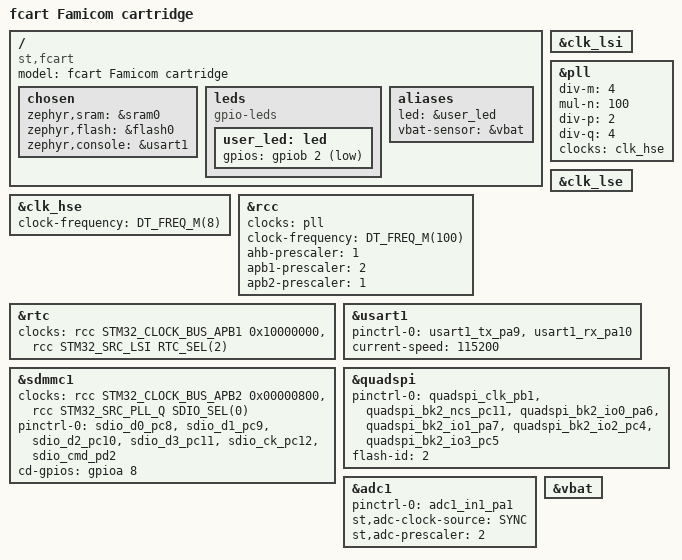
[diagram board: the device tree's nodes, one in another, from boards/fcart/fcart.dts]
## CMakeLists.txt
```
cmake_minimum_required(VERSION 3.20.0)
include(FetchContent)

set(BUILD_VERSION 3.7.1)
set(HAL_STM32_COMMIT f1317150eac951fdd8259337a47cbbc4c2e6d335)
set(CMSIS_COMMIT 4b96cbb174678dcd3ca86e11e1f24bc5f8726da0)
set(FATFS_COMMIT 427159bf95ea49b7680facffaa29ad506b42709b)
set(BOARD_ROOT ${CMAKE_CURRENT_SOURCE_DIR})
set(BOARD fcart)

set(NO_BUILD_TYPE_WARNING TRUE)
if(CMAKE_BUILD_TYPE STREQUAL "Debug")
    set(CONFIG_DEBUG y CACHE INTERNAL "Enable debug")
else()
    set(CONFIG_DEBUG n CACHE INTERNAL "Disable debug")
endif()

FetchContent_Declare(
    zephyr_distro
    DOWNLOAD_EXTRACT_TIMESTAMP TRUE
    URL https://github.com/zephyrproject-rtos/zephyr/archive/refs/tags/v${BUILD_VERSION}.tar.gz
    SOURCE_SUBDIR cmake # prevent cmake from being called inside the project
)
FetchContent_MakeAvailable(zephyr_distro)
FetchContent_Declare(
    hal_stm32
    DOWNLOAD_EXTRACT_TIMESTAMP TRUE
    URL https://github.com/zephyrproject-rtos/hal_stm32/archive/${HAL_STM32_COMMIT}.tar.gz
    SOURCE_SUBDIR cmake
    SOURCE_DIR "${CMAKE_CURRENT_BINARY_DIR}/modules/hal/stm32"
)
FetchContent_MakeAvailable(hal_stm32)
FetchContent_Declare(
    cmsis
    DOWNLOAD_EXTRACT_TIMESTAMP TRUE
    URL https://github.com/zephyrproject-rtos/cmsis/archive/${CMSIS_COMMIT}.tar.gz
    SOURCE_SUBDIR cmake
    SOURCE_DIR "${CMAKE_CURRENT_BINARY_DIR}/modules/hal/cmsis"
)
FetchContent_MakeAvailable(cmsis)
FetchContent_Declare(
    fatfs
    DOWNLOAD_EXTRACT_TIMESTAMP TRUE
    URL https://github.com/zephyrproject-rtos/fatfs/archive/${FATFS_COMMIT}.tar.gz
    SOURCE_SUBDIR cmake
    SOURCE_DIR "${CMAKE_CURRENT_BINARY_DIR}/modules/hal/fatfs"
)
FetchContent_MakeAvailable(fatfs)
set(ZEPHYR_MODULES ${hal_stm32_SOURCE_DIR} ${cmsis_SOURCE_DIR} ${fatfs_SOURCE_DIR})

find_package(Zephyr REQUIRED HINTS ${zephyr_distro_SOURCE_DIR})

project(fcart_sw)

add_subdirectory(src)
```

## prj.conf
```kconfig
CONFIG_LOG=y
CONFIG_SENSOR=y
CONFIG_ADC=y
```

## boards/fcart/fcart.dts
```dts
/dts-v1/;
#include <st/f4/stm32f412Xe.dtsi>
#include <st/f4/stm32f412r(e-g)tx-pinctrl.dtsi>

/ {
    model = "fcart Famicom cartridge";
    compatible = "st,fcart";

    chosen {
		zephyr,sram = &sram0;
		zephyr,flash = &flash0;
		zephyr,console = &usart1;
	};

    leds {
        compatible = "gpio-leds";
        user_led: led {
            gpios = <&gpiob 2 GPIO_ACTIVE_LOW>;
        };
    };

    aliases {
		led = &user_led;
		vbat-sensor = &vbat;
	};
};

&clk_lsi {
	status = "okay";
};

&clk_hse {
	clock-frequency = <DT_FREQ_M(8)>;
	status = "okay";
};

&pll {
	div-m = <4>;
	mul-n = <100>;
	div-p = <2>;
	div-q = <4>;
	clocks = <&clk_hse>;
	status = "okay";
};

&rcc {
	clocks = <&pll>;
	clock-frequency = <DT_FREQ_M(100)>;
	ahb-prescaler = <1>;
	apb1-prescaler = <2>;
	apb2-prescaler = <1>;
};

&clk_lse {
	status = "okay";
};

&rtc {
	clocks = <&rcc STM32_CLOCK_BUS_APB1 0x10000000>,
		 <&rcc STM32_SRC_LSI RTC_SEL(2)>;
	status = "okay";
};

&usart1 {
	pinctrl-0 = <&usart1_tx_pa9 &usart1_rx_pa10>;
	pinctrl-names = "default";
	current-speed = <115200>;
	status = "okay";
};

&sdmmc1 {
	clocks = <&rcc STM32_CLOCK_BUS_APB2 0x00000800>,
		<&rcc STM32_SRC_PLL_Q SDIO_SEL(0)>;
	status = "okay";
	pinctrl-0 = <&sdio_d0_pc8
		     &sdio_d1_pc9
		     &sdio_d2_pc10
		     &sdio_d3_pc11
		     &sdio_ck_pc12
		     &sdio_cmd_pd2>;
	pinctrl-names = "default";
	cd-gpios = <&gpioa 8 (GPIO_ACTIVE_HIGH | GPIO_PULL_UP)>;
};

&quadspi {
	pinctrl-0 = <&quadspi_clk_pb1 &quadspi_bk2_ncs_pc11
			&quadspi_bk2_io0_pa6 &quadspi_bk2_io1_pa7
		    &quadspi_bk2_io2_pc4 &quadspi_bk2_io3_pc5>;
	pinctrl-names = "default";
	flash-id = <2>;
	status = "okay";
};

&adc1 {
	pinctrl-0 = <&adc1_in1_pa1>;
	pinctrl-names = "default";
	st,adc-clock-source = <SYNC>;
	st,adc-prescaler = <2>;
	status = "okay";
};

&vbat {
	status = "okay";
};
```

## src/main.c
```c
#include "ui.h"
#include <ff.h>
#include <gpio.h>
#include <soc.h>
#include <tusb.h>

int main()
{
    hw_init();
    ui_init();

    for (;;) {
        gpio_poll();
        ui_poll();
        tud_task();
    }

    return 0;
}
```

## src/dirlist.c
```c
#include "dirlist.h"
#include "fpga_api.h"
#include "gfx.h"
#include <errno.h>
#include <ff.h>
#include <qspi.h>
#include <stdio.h>
#include <stdlib.h>
#include <string.h>

struct arr {
    uint32_t *items;
    uint16_t capacity;
    uint16_t count;
};

#define arr_append(a, v)                                               \
    do {                                                               \
        if (a.count >= a.capacity) {                                   \
            a.capacity = a.capacity == 0 ? 256 : a.capacity * 2;       \
            a.items = realloc(a.items, a.capacity * sizeof(*a.items)); \
        }                                                              \
        a.items[a.count++] = v;                                        \
    } while (0)

static struct arr items;
static uint16_t dir_count;
static char *curr_path;

typedef struct {
    uint32_t addr;
    char cache[11];
    uint8_t is_dir;
} cached_entry_t;

static int names_cmp(const void *a, const void *b);
static int readdir();

int dirlist_load()
{
    if (curr_path != NULL) {
        free(curr_path);
    }
    curr_path = malloc(1);
    curr_path[0] = '\0';

    return readdir();
}

int dirlist_push(const char *subdir)
{
    uint16_t subdir_len = strlen(subdir);
    uint16_t curr_path_len = strlen(curr_path);
    char *new_curr_path = malloc(curr_path_len + subdir_len + 2);
    if (new_curr_path == NULL) {
        return -ENOMEM;
    }

    strcpy(new_curr_path, curr_path);
    new_curr_path[curr_path_len] = '/';
    strcpy(&new_curr_path[curr_path_len + 1], subdir);

    free(curr_path);
    curr_path = new_curr_path;

    return readdir();
}

int dirlist_pop()
{
    char *last_slash = strrchr(curr_path, '/');
    if (last_slash != NULL) {
        *last_slash = '\0';
    } else {
        curr_path[0] = '\0';
    }
    return readdir();
}

uint16_t dirlist_size()
{
    return items.count;
}

uint8_t dirlist_select(uint16_t index, uint8_t limit, struct dirlist_entry *out)
{
    if (index >= items.count) {
        return 0; // Index out of bounds
    }

    uint8_t count = 0;
    uint16_t curr_index = index;

    while ((count < limit) && (curr_index < items.count)) {
        qspi_read(CMD_READ_MEM, items.items[curr_index], (uint8_t *)out[count].name, sizeof(out[count].name));
        out[count].is_dir = (curr_index < dir_count);

        count++;
        curr_index++;
    }
    return count; // Return number of entries filled
}

char *dirlist_file_path(struct dirlist_entry *entry)
{
    uint16_t curr_path_len = strlen(curr_path);
    uint16_t name_len = strlen(entry->name);
    char *full_path = malloc(curr_path_len + name_len + 2);
    if (full_path == NULL) {
        return NULL;
    }

    if (curr_path_len > 0) {
        strcpy(full_path, curr_path);
    }
    full_path[curr_path_len] = '/';
    strcpy(&full_path[curr_path_len + 1], entry->name);

    return full_path;
}

static int names_cmp(const void *a, const void *b)
{
    const cached_entry_t *ca = a;
    const cached_entry_t *cb = b;

    if (ca->is_dir != cb->is_dir) {
        return cb->is_dir - ca->is_dir;
    }

    int r = strncmp(ca->cache, cb->cache, sizeof(ca->cache));
    if (r != 0) {
        return r;
    }

    // Fallback to QSPI read
    char buf_a[256];
    char buf_b[256];
    qspi_read(CMD_READ_MEM, ca->addr, (uint8_t *)buf_a, sizeof(buf_a));
    qspi_read(CMD_READ_MEM, cb->addr, (uint8_t *)buf_b, sizeof(buf_b));
    return strcmp(buf_a, buf_b);
}

static int readdir()
{
    DIR dir;
    FILINFO fno;
    int r = 0;
    uint32_t sdram_addr = 0;

    if (f_opendir(&dir, curr_path) != FR_OK) {
        return false;
    }

    // Reset lists
    items.count = 0;
    dir_count = 0;

    struct {
        cached_entry_t *items;
        uint16_t capacity;
        uint16_t count;
    } cache_entries = { 0 };

    static uint8_t buf[512];
    uint16_t buf_len = 0;

    for (;;) {
        if (f_readdir(&dir, &fno) != FR_OK || fno.fname[0] == 0) {
            break;
        }
        if (fno.fname[0] == '.' || (fno.fattrib & AM_HID) || (fno.fattrib & AM_SYS)) {
            continue; // Skip hidden files
        }

        uint16_t name_len = strlen(fno.fname) + 1;
        uint16_t needed = name_len + (name_len % 2);

        if (buf_len + needed > sizeof(buf)) {
            if ((r = qspi_write(CMD_WRITE_MEM, sdram_addr, buf, buf_len)) != 0) {
                goto out;
            }
            sdram_addr += buf_len;
            buf_len = 0;
        }

        cached_entry_t entry;
        entry.addr = sdram_addr + buf_len;
        entry.is_dir = (fno.fattrib & AM_DIR) ? 1 : 0;
        memcpy(entry.cache, fno.fname, sizeof(entry.cache));

        arr_append(cache_entries, entry);
        if (cache_entries.items == NULL || cache_entries.count == UINT16_MAX) {
            r = -ENOSPC;
            goto out;
        }

        strcpy((char *)&buf[buf_len], fno.fname);
        if (needed > name_len)
            buf[buf_len + name_len] = 0;
        buf_len += needed;
    }

    if (buf_len > 0) {
        if ((r = qspi_write(CMD_WRITE_MEM, sdram_addr, buf, buf_len)) != 0) {
            goto out;
        }
    }

    if (cache_entries.count > 0)
        qsort(cache_entries.items, cache_entries.count, sizeof(cached_entry_t), names_cmp);

    for (uint16_t i = 0; i < cache_entries.count; i++) {
        arr_append(items, cache_entries.items[i].addr);
        if (cache_entries.items[i].is_dir) {
            dir_count++;
        }
    }
out:
    if (cache_entries.items)
        free(cache_entries.items);
    f_closedir(&dir);
    return r;
}
```

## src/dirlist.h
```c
#pragma once

#include <stdint.h>

struct dirlist_entry {
    char name[256];
    bool is_dir;
};

int dirlist_load();
int dirlist_push(const char *subdir);
int dirlist_pop();
uint16_t dirlist_size();
uint8_t dirlist_select(uint16_t index, uint8_t limit, struct dirlist_entry *out);
char *dirlist_file_path(struct dirlist_entry *entry);
```

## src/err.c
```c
#include "err.h"
#include <errno.h>

int fresult_to_errno(FRESULT rc)
{
    switch (rc) {
    case FR_OK:
        return 0;
    case FR_DISK_ERR:
        return EIO;
    case FR_INT_ERR:
        return EFAULT;
    case FR_NOT_READY:
        return EBUSY;
    case FR_NO_FILE:
        return ENOENT;
    case FR_NO_PATH:
        return ENOENT;
    case FR_INVALID_NAME:
        return EINVAL;
    case FR_DENIED:
        return EACCES;
    case FR_EXIST:
        return EEXIST;
    case FR_INVALID_OBJECT:
        return EINVAL;
    case FR_WRITE_PROTECTED:
        return EROFS;
    case FR_INVALID_DRIVE:
        return ENODEV;
    case FR_NOT_ENABLED:
        return ENODEV;
    case FR_NO_FILESYSTEM:
        return ENODEV;
    case FR_MKFS_ABORTED:
        return EIO;
    case FR_TIMEOUT:
        return ETIMEDOUT;
    case FR_LOCKED:
        return EBUSY;
    case FR_NOT_ENOUGH_CORE:
        return ENOMEM;
    case FR_TOO_MANY_OPEN_FILES:
        return EMFILE;
    case FR_INVALID_PARAMETER:
        return EINVAL;
    default:
        return EIO;
    }
}
```

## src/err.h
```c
#pragma once

#include <ff.h>

int fresult_to_errno(FRESULT rc);
```

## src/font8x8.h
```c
/**
 * Based on:
 *  Summary: font8x8.h
 *  8x8 monochrome bitmap fonts for rendering
 *
 *  Author:
 *      Marcel Sondaar
 *      International Business Machines (public domain VGA fonts)
 *
 *  License:
 *      Public Domain
 *
 * Fetched from: http://dimensionalrift.homelinux.net/combuster/mos3/?p=viewsource&file=/modules/gfx/font8_8.asm
 **/

const uint8_t font8x8[][8] = {
    { 0x00, 0x00, 0x00, 0x00, 0x00, 0x00, 0x00, 0x00 }, // U+0020 (space)
    { 0x18, 0x3C, 0x3C, 0x18, 0x18, 0x00, 0x18, 0x00 }, // U+0021 (!)
    { 0x36, 0x36, 0x00, 0x00, 0x00, 0x00, 0x00, 0x00 }, // U+0022 (")
    { 0x36, 0x36, 0x7F, 0x36, 0x7F, 0x36, 0x36, 0x00 }, // U+0023 (#)
    { 0x0C, 0x3E, 0x03, 0x1E, 0x30, 0x1F, 0x0C, 0x00 }, // U+0024 ($)
    { 0x00, 0x63, 0x33, 0x18, 0x0C, 0x66, 0x63, 0x00 }, // U+0025 (%)
    { 0x1C, 0x36, 0x1C, 0x6E, 0x3B, 0x33, 0x6E, 0x00 }, // U+0026 (&)
    { 0x06, 0x06, 0x03, 0x00, 0x00, 0x00, 0x00, 0x00 }, // U+0027 (')
    { 0x18, 0x0C, 0x06, 0x06, 0x06, 0x0C, 0x18, 0x00 }, // U+0028 (()
    { 0x06, 0x0C, 0x18, 0x18, 0x18, 0x0C, 0x06, 0x00 }, // U+0029 ())
    { 0x00, 0x66, 0x3C, 0xFF, 0x3C, 0x66, 0x00, 0x00 }, // U+002A (*)
    { 0x00, 0x0C, 0x0C, 0x3F, 0x0C, 0x0C, 0x00, 0x00 }, // U+002B (+)
    { 0x00, 0x00, 0x00, 0x00, 0x00, 0x0C, 0x0C, 0x06 }, // U+002C (,)
    { 0x00, 0x00, 0x00, 0x3F, 0x00, 0x00, 0x00, 0x00 }, // U+002D (-)
    { 0x00, 0x00, 0x00, 0x00, 0x00, 0x0C, 0x0C, 0x00 }, // U+002E (.)
    { 0x60, 0x30, 0x18, 0x0C, 0x06, 0x03, 0x01, 0x00 }, // U+002F (/)
    { 0x3E, 0x63, 0x73, 0x7B, 0x6F, 0x67, 0x3E, 0x00 }, // U+0030 (0)
    { 0x0C, 0x0E, 0x0C, 0x0C, 0x0C, 0x0C, 0x3F, 0x00 }, // U+0031 (1)
    { 0x1E, 0x33, 0x30, 0x1C, 0x06, 0x33, 0x3F, 0x00 }, // U+0032 (2)
    { 0x1E, 0x33, 0x30, 0x1C, 0x30, 0x33, 0x1E, 0x00 }, // U+0033 (3)
    { 0x38, 0x3C, 0x36, 0x33, 0x7F, 0x30, 0x78, 0x00 }, // U+0034 (4)
    { 0x3F, 0x03, 0x1F, 0x30, 0x30, 0x33, 0x1E, 0x00 }, // U+0035 (5)
    { 0x1C, 0x06, 0x03, 0x1F, 0x33, 0x33, 0x1E, 0x00 }, // U+0036 (6)
    { 0x3F, 0x33, 0x30, 0x18, 0x0C, 0x0C, 0x0C, 0x00 }, // U+0037 (7)
    { 0x1E, 0x33, 0x33, 0x1E, 0x33, 0x33, 0x1E, 0x00 }, // U+0038 (8)
    { 0x1E, 0x33, 0x33, 0x3E, 0x30, 0x18, 0x0E, 0x00 }, // U+0039 (9)
    { 0x00, 0x0C, 0x0C, 0x00, 0x00, 0x0C, 0x0C, 0x00 }, // U+003A (:)
    { 0x00, 0x0C, 0x0C, 0x00, 0x00, 0x0C, 0x0C, 0x06 }, // U+003B (;)
    { 0x18, 0x0C, 0x06, 0x03, 0x06, 0x0C, 0x18, 0x00 }, // U+003C (<)
    { 0x00, 0x00, 0x3F, 0x00, 0x00, 0x3F, 0x00, 0x00 }, // U+003D (=)
    { 0x06, 0x0C, 0x18, 0x30, 0x18, 0x0C, 0x06, 0x00 }, // U+003E (>)
    { 0x1E, 0x33, 0x30, 0x18, 0x0C, 0x00, 0x0C, 0x00 }, // U+003F (?)
    { 0x3E, 0x63, 0x7B, 0x7B, 0x7B, 0x03, 0x1E, 0x00 }, // U+0040 (@)
    { 0x0C, 0x1E, 0x33, 0x33, 0x3F, 0x33, 0x33, 0x00 }, // U+0041 (A)
    { 0x3F, 0x66, 0x66, 0x3E, 0x66, 0x66, 0x3F, 0x00 }, // U+0042 (B)
    { 0x3C, 0x66, 0x03, 0x03, 0x03, 0x66, 0x3C, 0x00 }, // U+0043 (C)
    { 0x1F, 0x36, 0x66, 0x66, 0x66, 0x36, 0x1F, 0x00 }, // U+0044 (D)
    { 0x7F, 0x46, 0x16, 0x1E, 0x16, 0x46, 0x7F, 0x00 }, // U+0045 (E)
    { 0x7F, 0x46, 0x16, 0x1E, 0x16, 0x06, 0x0F, 0x00 }, // U+0046 (F)
    { 0x3C, 0x66, 0x03, 0x03, 0x73, 0x66, 0x7C, 0x00 }, // U+0047 (G)
    { 0x33, 0x33, 0x33, 0x3F, 0x33, 0x33, 0x33, 0x00 }, // U+0048 (H)
    { 0x1E, 0x0C, 0x0C, 0x0C, 0x0C, 0x0C, 0x1E, 0x00 }, // U+0049 (I)
    { 0x78, 0x30, 0x30, 0x30, 0x33, 0x33, 0x1E, 0x00 }, // U+004A (J)
    { 0x67, 0x66, 0x36, 0x1E, 0x36, 0x66, 0x67, 0x00 }, // U+004B (K)
    { 0x0F, 0x06, 0x06, 0x06, 0x46, 0x66, 0x7F, 0x00 }, // U+004C (L)
    { 0x63, 0x77, 0x7F, 0x7F, 0x6B, 0x63, 0x63, 0x00 }, // U+004D (M)
    { 0x63, 0x67, 0x6F, 0x7B, 0x73, 0x63, 0x63, 0x00 }, // U+004E (N)
    { 0x1C, 0x36, 0x63, 0x63, 0x63, 0x36, 0x1C, 0x00 }, // U+004F (O)
    { 0x3F, 0x66, 0x66, 0x3E, 0x06, 0x06, 0x0F, 0x00 }, // U+0050 (P)
    { 0x1E, 0x33, 0x33, 0x33, 0x3B, 0x1E, 0x38, 0x00 }, // U+0051 (Q)
    { 0x3F, 0x66, 0x66, 0x3E, 0x36, 0x66, 0x67, 0x00 }, // U+0052 (R)
    { 0x1E, 0x33, 0x07, 0x0E, 0x38, 0x33, 0x1E, 0x00 }, // U+0053 (S)
    { 0x3F, 0x2D, 0x0C, 0x0C, 0x0C, 0x0C, 0x1E, 0x00 }, // U+0054 (T)
    { 0x33, 0x33, 0x33, 0x33, 0x33, 0x33, 0x3F, 0x00 }, // U+0055 (U)
    { 0x33, 0x33, 0x33, 0x33, 0x33, 0x1E, 0x0C, 0x00 }, // U+0056 (V)
    { 0x63, 0x63, 0x63, 0x6B, 0x7F, 0x77, 0x63, 0x00 }, // U+0057 (W)
    { 0x63, 0x63, 0x36, 0x1C, 0x1C, 0x36, 0x63, 0x00 }, // U+0058 (X)
    { 0x33, 0x33, 0x33, 0x1E, 0x0C, 0x0C, 0x1E, 0x00 }, // U+0059 (Y)
    { 0x7F, 0x63, 0x31, 0x18, 0x4C, 0x66, 0x7F, 0x00 }, // U+005A (Z)
    { 0x1E, 0x06, 0x06, 0x06, 0x06, 0x06, 0x1E, 0x00 }, // U+005B ([)
    { 0x03, 0x06, 0x0C, 0x18, 0x30, 0x60, 0x40, 0x00 }, // U+005C (\)
    { 0x1E, 0x18, 0x18, 0x18, 0x18, 0x18, 0x1E, 0x00 }, // U+005D (])
    { 0x08, 0x1C, 0x36, 0x63, 0x00, 0x00, 0x00, 0x00 }, // U+005E (^)
    { 0x00, 0x00, 0x00, 0x00, 0x00, 0x00, 0x00, 0xFF }, // U+005F (_)
    { 0x0C, 0x0C, 0x18, 0x00, 0x00, 0x00, 0x00, 0x00 }, // U+0060 (`)
    { 0x00, 0x00, 0x1E, 0x30, 0x3E, 0x33, 0x6E, 0x00 }, // U+0061 (a)
    { 0x07, 0x06, 0x06, 0x3E, 0x66, 0x66, 0x3B, 0x00 }, // U+0062 (b)
    { 0x00, 0x00, 0x1E, 0x33, 0x03, 0x33, 0x1E, 0x00 }, // U+0063 (c)
    { 0x38, 0x30, 0x30, 0x3e, 0x33, 0x33, 0x6E, 0x00 }, // U+0064 (d)
    { 0x00, 0x00, 0x1E, 0x33, 0x3f, 0x03, 0x1E, 0x00 }, // U+0065 (e)
    { 0x1C, 0x36, 0x06, 0x0f, 0x06, 0x06, 0x0F, 0x00 }, // U+0066 (f)
    { 0x00, 0x00, 0x6E, 0x33, 0x33, 0x3E, 0x30, 0x1F }, // U+0067 (g)
    { 0x07, 0x06, 0x36, 0x6E, 0x66, 0x66, 0x67, 0x00 }, // U+0068 (h)
    { 0x0C, 0x00, 0x0E, 0x0C, 0x0C, 0x0C, 0x1E, 0x00 }, // U+0069 (i)
    { 0x30, 0x00, 0x30, 0x30, 0x30, 0x33, 0x33, 0x1E }, // U+006A (j)
    { 0x07, 0x06, 0x66, 0x36, 0x1E, 0x36, 0x67, 0x00 }, // U+006B (k)
    { 0x0E, 0x0C, 0x0C, 0x0C, 0x0C, 0x0C, 0x1E, 0x00 }, // U+006C (l)
    { 0x00, 0x00, 0x33, 0x7F, 0x7F, 0x6B, 0x63, 0x00 }, // U+006D (m)
    { 0x00, 0x00, 0x1F, 0x33, 0x33, 0x33, 0x33, 0x00 }, // U+006E (n)
    { 0x00, 0x00, 0x1E, 0x33, 0x33, 0x33, 0x1E, 0x00 }, // U+006F (o)
    { 0x00, 0x00, 0x3B, 0x66, 0x66, 0x3E, 0x06, 0x0F }, // U+0070 (p)
    { 0x00, 0x00, 0x6E, 0x33, 0x33, 0x3E, 0x30, 0x78 }, // U+0071 (q)
    { 0x00, 0x00, 0x3B, 0x6E, 0x66, 0x06, 0x0F, 0x00 }, // U+0072 (r)
    { 0x00, 0x00, 0x3E, 0x03, 0x1E, 0x30, 0x1F, 0x00 }, // U+0073 (s)
    { 0x08, 0x0C, 0x3E, 0x0C, 0x0C, 0x2C, 0x18, 0x00 }, // U+0074 (t)
    { 0x00, 0x00, 0x33, 0x33, 0x33, 0x33, 0x6E, 0x00 }, // U+0075 (u)
    { 0x00, 0x00, 0x33, 0x33, 0x33, 0x1E, 0x0C, 0x00 }, // U+0076 (v)
    { 0x00, 0x00, 0x63, 0x6B, 0x7F, 0x7F, 0x36, 0x00 }, // U+0077 (w)
    { 0x00, 0x00, 0x63, 0x36, 0x1C, 0x36, 0x63, 0x00 }, // U+0078 (x)
    { 0x00, 0x00, 0x33, 0x33, 0x33, 0x3E, 0x30, 0x1F }, // U+0079 (y)
    { 0x00, 0x00, 0x3F, 0x19, 0x0C, 0x26, 0x3F, 0x00 }, // U+007A (z)
    { 0x38, 0x0C, 0x0C, 0x07, 0x0C, 0x0C, 0x38, 0x00 }, // U+007B ({)
    { 0x18, 0x18, 0x18, 0x00, 0x18, 0x18, 0x18, 0x00 }, // U+007C (|)
    { 0x07, 0x0C, 0x0C, 0x38, 0x0C, 0x0C, 0x07, 0x00 }, // U+007D (})
    { 0x6E, 0x3B, 0x00, 0x00, 0x00, 0x00, 0x00, 0x00 }, // U+007E (~)
};
```

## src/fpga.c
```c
#include "fpga.h"
#include "sdio.h"

void fpga_init()
{
    sdio_init(10, 11, 12, 100);
}

void fpga_write_prg(uint32_t size, fpga_reader_cb cb, void *arg)
{
    for (uint32_t i = 0; i < size / 2; i++) {
        uint16_t data;
        if (!cb(&data, arg)) {
            return;
        }
        sdio_cmd_R1(1, i << 16u | data, NULL);
    }
}

void fpga_write_chr(uint32_t size, fpga_reader_cb cb, void *arg)
{
    for (uint32_t i = 0; i < size / 2; i++) {
        uint16_t data;
        if (!cb(&data, arg)) {
            return;
        }
        sdio_cmd_R1(2, i << 16u | data, NULL);
    }
}

void fpga_load()
{
    sdio_cmd_R1(3, 1, NULL);
}

void fpga_launch()
{
    sdio_cmd_R1(3, 0, NULL);
}
```

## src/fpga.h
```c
#pragma once

#include <stdbool.h>
#include <stdint.h>

typedef bool (*fpga_reader_cb)(uint16_t *, void *);

void fpga_init();
void fpga_write_prg(uint32_t size, fpga_reader_cb cb, void *arg);
void fpga_write_chr(uint32_t size, fpga_reader_cb cb, void *arg);
void fpga_load();
void fpga_launch();
```

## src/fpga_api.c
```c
#include "fpga_api.h"
#include <errno.h>
#include <gpio.h>
#include <qspi.h>
#include <stddef.h>
#include <stdlib.h>

#define BUF_SIZE 512

int fpga_api_write_mem(uint32_t address, uint32_t size, fpga_api_reader_cb cb, void *arg)
{
    static uint8_t buf[2][BUF_SIZE * 2];
    uint8_t buf_idx = 0;
    uint32_t remain = size;
    uint32_t offset = address;
    bool pending_write = false;
    int rc = 0;

    while (remain > 0) {
        uint32_t chunk = remain > BUF_SIZE ? BUF_SIZE : remain;
        if (!cb(buf[buf_idx], chunk, arg)) {
            rc = -EIO;
            goto out;
        }

        if (pending_write) {
            if ((rc = qspi_write_end()) != 0) {
                goto out;
            }
        }
        if ((rc = qspi_write_begin(CMD_WRITE_MEM, offset, buf[buf_idx], chunk)) != 0) {
            goto out;
        }
        pending_write = true;

        // Swap between two buffers for double-buffering
        buf_idx = !buf_idx;
        offset += chunk;
        remain -= chunk;
    }

    if (pending_write) {
        if ((rc = qspi_write_end()) != 0) {
            goto out;
        }
    }
out:
    return rc;
}

int fpga_api_read_mem(uint32_t address, uint32_t size, fpga_api_writer_cb cb, void *arg)
{
    static uint8_t buf[2][BUF_SIZE];
    uint32_t remain = size;
    uint32_t offset = address;
    int rc = 0;
    uint8_t buf_idx = 0;

    uint32_t chunk = remain > BUF_SIZE ? BUF_SIZE : remain;
    if ((rc = qspi_read_begin(CMD_READ_MEM, offset, buf[buf_idx], chunk)) != 0) {
        goto out;
    }

    while (remain > 0) {
        if ((rc = qspi_read_end()) != 0) {
            goto out;
        }

        uint32_t current_chunk = chunk;
        uint8_t current_buf_idx = buf_idx;

        offset += current_chunk;
        remain -= current_chunk;
        buf_idx = !buf_idx;

        if (remain > 0) {
            chunk = remain > BUF_SIZE ? BUF_SIZE : remain;
            if ((rc = qspi_read_begin(CMD_READ_MEM, offset, buf[buf_idx], chunk)) != 0) {
                goto out;
            }
        }

        if (!cb(buf[current_buf_idx], current_chunk, arg)) {
            rc = -EIO;
            if (remain > 0) {
                qspi_read_end();
            }
            goto out;
        }
    }
out:
    return rc;
}

int fpga_api_read_reg(enum fpga_reg_id id, uint32_t *value)
{
    return qspi_read(CMD_READ_REG, id, (uint8_t *)value, sizeof(uint32_t));
}

int fpga_api_write_reg(enum fpga_reg_id id, uint32_t value)
{
    return qspi_write(CMD_WRITE_REG, id, (uint8_t *)&value, sizeof(value));
}

uint32_t fpga_api_ev_reg(void)
{
    static uint32_t cached_events;
    static bool events_initialized;

    if (irq_called() || !events_initialized) {
        if (fpga_api_read_reg(FPGA_REG_EVENTS, &cached_events) == 0) {
            events_initialized = true;
        }
    }
    return cached_events;
}
```

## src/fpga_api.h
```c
#pragma once

#include <stdint.h>

enum {
    CMD_READ_MEM = 0,
    CMD_WRITE_MEM,
    CMD_READ_REG,
    CMD_WRITE_REG
};

enum fpga_reg_id {
    FPGA_REG_MAPPER = 0,
    FPGA_REG_LAUNCHER = 1,
    FPGA_REG_EVENTS = 1
};

typedef bool (*fpga_api_reader_cb)(uint8_t *, uint32_t, void *);
typedef bool (*fpga_api_writer_cb)(const uint8_t *, uint32_t, void *);

int fpga_api_write_mem(uint32_t address, uint32_t size, fpga_api_reader_cb cb, void *arg);
int fpga_api_read_mem(uint32_t address, uint32_t size, fpga_api_writer_cb cb, void *arg);

int fpga_api_read_reg(enum fpga_reg_id id, uint32_t *value);
int fpga_api_write_reg(enum fpga_reg_id id, uint32_t value);
uint32_t fpga_api_ev_reg();
```

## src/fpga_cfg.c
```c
#include "fpga_cfg.h"
#include "log.h"
#include <errno.h>
#include <soc.h>
#include <spi.h>
#include <string.h>

LOG_MODULE(fpga_cfg);

#define IDCODE_PUB { 0xE0, 0x00, 0x00, 0x00 }
#define LSC_READ_STATUS { 0x3C, 0x00, 0x00, 0x00 }
#define ISC_ENABLE_X { 0x74, 0x08, 0x00, 0x00 }
#define ISC_ERASE { 0x0E, 0x04, 0x00, 0x00 } // 0x12 for cfg and UFM
#define LSC_INITADDRESS { 0x46, 0x00, 0x00, 0x00 }
#define LSC_PROG_INCR_NV { 0x70, 0x00, 0x00, 0x01 }
#define ISC_PROGRAM_DONE { 0x5E, 0x00, 0x00, 0x00 }
#define ISC_DISABLE { 0x26, 0x00, 0x00 }
#define LSC_REFRESH { 0x79, 0x00, 0x00 }

#define PAGE_SIZE 16

enum status_bit {
    BIT_DONE = 8,
    BIT_BUSY = 12,
    BIT_FAIL = 13,
};

static int read_device_id(uint32_t *id);
static int get_status(uint32_t *status);
static bool test_bit(uint32_t status, enum status_bit bit);
static int enable_cfg_interface();
static int disable_cfg_interface();
static int init_address();
static int write_page(uint8_t *data);
static int program_done();
static int erase_flash();
static int refresh();
static void cleanup();
static void dump_status(uint32_t status);

int fpga_cfg_start()
{
    uint32_t id, status;
    int rc;

    LOG_INF("Initializing FPGA flash...");
    get_status(&status);
    dump_status(status);

    if ((rc = read_device_id(&id)) != 0) {
        return rc;
    }
    LOG_INF("FPGA ID: %08X", id);

    if (id != 0x012BC043) {
        LOG_ERR("Invalid FPGA ID");
        return -ENODEV;
    }

    if ((rc = enable_cfg_interface()) != 0) {
        return rc;
    }

    if ((rc = erase_flash()) != 0) {
        return rc;
    }

    if ((rc = get_status(&status)) != 0) {
        return rc;
    }
    dump_status(status);
    if (test_bit(status, BIT_FAIL)) {
        LOG_ERR("FPGA flash erase failed");
        return -EINVAL;
    }

    // When programming the UFM, must make this call again.
    rc = init_address();

    get_status(&status);
    dump_status(status);
    return rc;
}

int fpga_cfg_write(uint8_t *data, uint32_t len)
{
    uint8_t tail_buf[PAGE_SIZE] = { [0 ... PAGE_SIZE - 1] = 0xFF };
    uint8_t *tx;
    uint32_t status;
    int rc;

    LOG_INF("Writing %u bytes to FPGA flash", len);
    get_status(&status);
    dump_status(status);

    for (uint32_t offset = 0; offset < len; offset += PAGE_SIZE) {
        if (len - offset < PAGE_SIZE) {
            memcpy(tail_buf, &data[offset], len - offset);
            tx = tail_buf;
        } else {
            tx = &data[offset];
        }
        if ((rc = write_page(tx)) != 0) {
            return rc;
        }
    }

    get_status(&status);
    dump_status(status);
    return 0;
}

int fpga_cfg_done()
{
    uint32_t status;
    int rc;

    LOG_INF("Finalizing FPGA flash programming...");

    if ((rc = program_done()) != 0) {
        return rc;
    }

    if ((rc = get_status(&status)) != 0) {
        return rc;
    }
    dump_status(status);
    if (!test_bit(status, BIT_DONE)) {
        LOG_ERR("FPGA flash programming failed");
        cleanup();
        return -EINVAL;
    }

    // If offline programming is to be used, a LSC_REFRESH must be do instead of this call.
    rc = disable_cfg_interface();

    get_status(&status);
    dump_status(status);
    return rc;
}

static uint32_t to_le(uint8_t word[4])
{
    return ((word[0] << 24U) | (word[1] << 16U) | (word[2] << 8U) | word[3]);
}

static int read_device_id(uint32_t *id)
{
    uint8_t buf[] = IDCODE_PUB;
    int rc;

    spi_begin();
    if ((rc = spi_send(buf, sizeof(buf))) != 0) {
        goto out;
    }
    if ((rc = spi_recv(buf, sizeof(buf))) != 0) {
        goto out;
    }
    *id = to_le(buf);
out:
    spi_end();
    return rc;
}

static int get_status(uint32_t *status)
{
    uint8_t buf[] = LSC_READ_STATUS;
    int rc;

    spi_begin();
    if ((rc = spi_send(buf, sizeof(buf))) != 0) {
        goto out;
    }
    if ((rc = spi_recv(buf, sizeof(buf))) != 0) {
        goto out;
    }
    *status = to_le(buf);
out:
    spi_end();
    return rc;
}

static bool test_bit(uint32_t status, enum status_bit bit)
{
    return (status & (1U << bit)) != 0;
}

static int wait_until_ready(uint32_t poll_us)
{
    uint32_t status;
    int rc;
    int retry_count = 0;

    do {
        if ((rc = get_status(&status)) != 0) {
            return rc;
        }
        if (++retry_count >= 10) {
            LOG_ERR("Timeout waiting for FPGA to become ready");
            return -EBUSY;
        }
        if (poll_us > 1000U) {
            delay_ms(poll_us / 1000U);
        } else {
            delay_us(poll_us);
        }
    } while (test_bit(status, BIT_BUSY));

    return 0;
}

static int enable_cfg_interface()
{
    uint8_t buf[] = ISC_ENABLE_X;
    int rc;

    spi_begin();
    rc = spi_send(buf, sizeof(buf));
    spi_end();

    return rc == 0 ? wait_until_ready(2U) : rc;
}

static int disable_cfg_interface()
{
    uint8_t buf[] = ISC_DISABLE;
    int rc;

    spi_begin();
    rc = spi_send(buf, sizeof(buf));
    spi_end();

    return rc;
}

static int init_address()
{
    uint8_t buf[] = LSC_INITADDRESS;
    int rc;

    spi_begin();
    rc = spi_send(buf, sizeof(buf));
    spi_end();

    return rc;
}

static int write_page(uint8_t *data)
{
    uint8_t cmd[] = LSC_PROG_INCR_NV;
    int rc;

    spi_begin();
    if ((rc = spi_send(cmd, sizeof(cmd))) != 0) {
        spi_end();
        return rc;
    }
    rc = spi_send(data, PAGE_SIZE);
    spi_end();

    // The operation takes 200 us.
    // Therefore we will poll every 50 us.
    return rc == 0 ? wait_until_ready(50U) : rc;
}

static int program_done()
{
    uint8_t buf[] = ISC_PROGRAM_DONE;
    int rc;

    spi_begin();
    rc = spi_send(buf, sizeof(buf));
    spi_end();

    return rc == 0 ? wait_until_ready(50U) : rc;
}

static int erase_flash()
{
    uint8_t buf[] = ISC_ERASE;
    int rc;

    spi_begin();
    rc = spi_send(buf, sizeof(buf));
    spi_end();

    // Takes 5 seconds for the largest device.
    return rc == 0 ? wait_until_ready(1000U * 1000U) : rc;
}

static int refresh()
{
    uint8_t buf[] = LSC_REFRESH;
    int rc;

    spi_begin();
    rc = spi_send(buf, sizeof(buf));
    spi_end();

    // Takes a few milliseconds depending on the model.
    // We will poll once per millisecond.
    return rc == 0 ? wait_until_ready(1000U) : rc;
}

static void cleanup()
{
    LOG_INF("Cleaning up FPGA flash state...");

    if (erase_flash() == 0) {
        refresh();
    }
}

static const char *err_string(uint8_t err)
{
    switch (err) {
    case 0:
        return "No Error";
    case 1:
        return "ID ERR";
    case 2:
        return "CMD ERR";
    case 3:
        return "CRC ERR";
    case 4:
        return "Preamble ERR";
    case 5:
        return "Abort ERR";
    case 6:
        return "Overflow ERR";
    case 7:
        return "SDM EOF";
    default:
        return "Unknown Error";
    }
}

static void dump_status(uint32_t status)
{
    LOG_INF("FPGA flash status: %08X", status);
    LOG_INF("  DONE: %d", test_bit(status, BIT_DONE));
    LOG_INF("  ISC Enable: %d", test_bit(status, 9U));
    LOG_INF("  BUSY: %d", test_bit(status, BIT_BUSY));
    LOG_INF("  FAIL: %d", test_bit(status, BIT_FAIL));
    LOG_INF("  ID Error: %d", test_bit(status, 27U));
    LOG_INF("  Error: %s", err_string((status >> 23U) & 7U));
}
```

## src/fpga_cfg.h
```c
#pragma once

#include <stdint.h>

int fpga_cfg_put(uint8_t *data, uint32_t len);
```

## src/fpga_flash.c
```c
#include "fpga_flash.h"
#include "altera.h"
#include "trace.h"
#include <hardware/gpio.h>
#include <pico/multicore.h>
#include <stdlib.h>
#include <zlib.h>

#define JTAG_PIN_TCK 6
#define JTAG_PIN_TDO 7
#define JTAG_PIN_TMS 8
#define JTAG_PIN_TDI 9

// Embedding fpga configuration into binary
// clang-format off
#define INCBIN(name, file)                      \
    __asm__(".section .rodata\n"                \
            ".global _binary_" #name "_start\n" \
            ".balign 16\n"                      \
            "_binary_" #name "_start:\n"        \
            ".incbin \"" file "\"\n"            \
            ".global _binary_" #name "_end\n"   \
            ".balign 1\n"                       \
            "_binary_" #name "_end:\n"          \
            ".byte 0\n");                       \
    extern __attribute__((aligned(16))) const uint8_t _binary_##name##_start[]; \
    extern const uint8_t _binary_##name##_end[]
// clang-format on

INCBIN(loader, LOADER_ARCHIVE_PATH);
INCBIN(fcart, FCART_ARCHIVE_PATH);

// Write in one buffer and read from another.
struct inflate_data {
    uint8_t *buf;
    uint16_t sz;
    bool last;
    bool err;
};

static struct inflate_data inflate_res[2];
static uint16_t inflate_chunk;
static const uint8_t *inflate_start, *inflate_end;
static void inflate_thread()
{
    multicore_fifo_drain();

    z_stream strm;
    strm.zalloc = Z_NULL;
    strm.zfree = Z_NULL;
    strm.opaque = Z_NULL;
    strm.avail_in = inflate_end - inflate_start;
    strm.next_in = inflate_start;

    inflateInit2(&strm, 16 + MAX_WBITS);
    bool curr_buf = 0;

    for (;;) {
        struct inflate_data *res = &inflate_res[curr_buf];

        strm.next_out = res->buf;
        strm.avail_out = inflate_chunk;

        int ret = inflate(&strm, Z_NO_FLUSH);
        if (ret != Z_OK && ret != Z_STREAM_END) {
            TRACE("zlib error (%d): %s", ret, strm.msg);
        }

        res->sz = inflate_chunk - strm.avail_out;
        res->last = (ret == Z_STREAM_END);
        res->err = (ret != Z_OK && ret != Z_STREAM_END);
        multicore_fifo_push_blocking(curr_buf);
        curr_buf ^= 1;

        if (ret != Z_OK) {
            break;
        }
        if (multicore_fifo_pop_blocking() != 0) {
            break;
        }
    }
    inflateEnd(&strm);
    TRACE("zlib finish");
}

static void start_inflate(uint16_t chunk, const uint8_t *start_addr, const uint8_t *end_addr)
{
    inflate_res[0].buf = malloc(chunk);
    inflate_res[1].buf = malloc(chunk);

    inflate_start = start_addr;
    inflate_end = end_addr;
    inflate_chunk = chunk;
    multicore_reset_core1();
    multicore_launch_core1(inflate_thread);
}

static void stop_inflate(bool abort)
{
    if (abort) {
        multicore_fifo_push_blocking(1);
    }
    multicore_fifo_drain();
    free(inflate_res[0].buf);
    free(inflate_res[1].buf);
}

static int32_t push_loader(uint32_t **buf, bool *last)
{
    uint32_t n = multicore_fifo_pop_blocking();
    struct inflate_data *res = &inflate_res[n];
    if (res->err) {
        return -1;
    }
    *buf = (uint32_t *)res->buf;
    *last = res->last;
    multicore_fifo_push_blocking(0);
    return res->sz;
}

static bool write_enable()
{
    alt_flash_exec(0x06, 0);
    return alt_flash_wait(0x05, 0x02, 0x02, 15);
}

// 32KB Blocks Erase
static bool blocks_erase(uint32_t addr, uint32_t nbytes)
{
    for (uint32_t block = addr; block < nbytes; block += 0x8000) {
        if (!write_enable()) {
            TRACE("fpga_flash: we error while block erase");
            return false;
        }
        alt_flash_rw(0x52, block, NULL, NULL, 0);
        if (!alt_flash_wait(0x05, 0x00, 0x01, 1600)) {
            TRACE("fpga_flash: block erase timeout");
            return false;
        }
    }
    return true;
}

static bool page_program(uint32_t addr, uint32_t *data, uint32_t nbytes)
{
    assert(nbytes <= 256);
    if (!write_enable()) {
        TRACE("fpga_flash: we error while page program");
        return false;
    }
    alt_flash_rw(0x02, addr, data, NULL, nbytes);
    if (!alt_flash_wait(0x05, 0x00, 0x01, 3)) {
        TRACE("fpga_flash: page program timeout");
        return false;
    }
    return true;
}

static bool flash_program()
{
    start_inflate(256, _binary_fcart_start, _binary_fcart_end);

    struct inflate_data *res;
    uint32_t addr = 0;
    bool ret = true;
    do {
        uint32_t n = multicore_fifo_pop_blocking();
        res = &inflate_res[n];
        if (res->err) {
            ret = false;
            goto out;
        }
        multicore_fifo_push_blocking(0);

        if (!page_program(addr, (uint32_t *)res->buf, res->sz)) {
            ret = false;
            goto out;
        }
        addr += res->sz;
    } while (!res->last);

out:
    stop_inflate(!ret);
    return ret;
}

static uint32_t calc_crc(uint32_t size)
{
    uint8_t buf[256];
    uLong crc = crc32(0L, Z_NULL, 0);

    for (uint32_t addr = 0; addr < size; addr += 256) {
        uint32_t sz = (size - addr) < 256 ? (size - addr) : 256;
        alt_flash_rw(0x03, addr, NULL, (uint32_t *)buf, sz);
        crc = crc32(crc, buf, sz);
    }
    return crc;
}

bool fpga_flash()
{
    // Launch unzip in a separate core
    start_inflate(512, _binary_loader_start, _binary_loader_end);

    alt_init(6, 7, 8, 9);
    if (!alt_scan()) {
        TRACE("fpga not found");
        return false;
    }
    if (!alt_program_mem(push_loader)) {
        TRACE("fpga_flash: error while programming the loader");
        return false;
    }

    stop_inflate(false);

    // Reset
    alt_flash_exec(0x66, 0);
    alt_flash_exec(0x99, 0);
    alt_flash_exec(0xAB, 0);

    uint32_t id = alt_flash_exec(0x9F, 3);
    if (id != 0xEF4017) {
        TRACE("fpga_flash: unsupported memory: 0x%08lx", id);
        return false;
    }

    uint32_t status = alt_flash_exec(0x05, 1);
    if (status != 0) {
        TRACE("fpga_flash: write protection set: %lu", status);
        return false;
    }

    uint32_t size = *(uint32_t *)(_binary_fcart_end - 4);
    if (!blocks_erase(0, size)) {
        return false;
    }

    if (!flash_program()) {
        return false;
    }

    uint32_t crc = *(uint32_t *)(_binary_fcart_end - 8);
    if (calc_crc(size) != crc) {
        TRACE("fpga_flash: checksum mismatch");
        return false;
    }

    alt_reset();
    return true;
}
```
